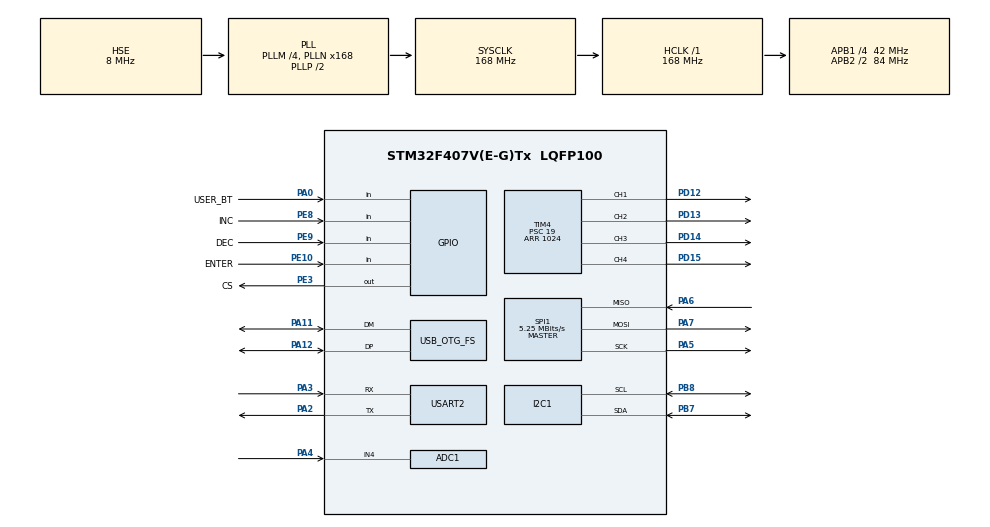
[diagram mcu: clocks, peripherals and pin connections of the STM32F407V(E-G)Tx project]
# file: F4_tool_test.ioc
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ADC1.Channel-5\#ChannelRegularConversion=ADC_CHANNEL_4
ADC1.ClockPrescaler=ADC_CLOCK_SYNC_PCLK_DIV8
ADC1.ContinuousConvMode=ENABLE
ADC1.EOCSelection=ADC_EOC_SEQ_CONV
ADC1.InjNumberOfConversion=0
ADC1.NbrOfConversion=1
ADC1.NbrOfConversionFlag=1
ADC1.Rank-5\#ChannelRegularConversion=1
ADC1.SamplingTime-5\#ChannelRegularConversion=ADC_SAMPLETIME_480CYCLES
ADC1.master=1
Dma.Request0=USART2_TX
Dma.Request1=USART2_RX
Dma.USART2_RX.1.Direction=DMA_PERIPH_TO_MEMORY
Dma.USART2_RX.1.FIFOMode=DMA_FIFOMODE_DISABLE
Dma.USART2_RX.1.Instance=DMA1_Stream5
Dma.USART2_RX.1.MemDataAlignment=DMA_MDATAALIGN_BYTE
Dma.USART2_RX.1.MemInc=DMA_MINC_ENABLE
Dma.USART2_RX.1.Mode=DMA_CIRCULAR
Dma.USART2_RX.1.PeriphDataAlignment=DMA_PDATAALIGN_BYTE
Dma.USART2_RX.1.PeriphInc=DMA_PINC_DISABLE
Dma.USART2_RX.1.Priority=DMA_PRIORITY_LOW
Dma.USART2_TX.0.Direction=DMA_MEMORY_TO_PERIPH
Dma.USART2_TX.0.FIFOMode=DMA_FIFOMODE_DISABLE
Dma.USART2_TX.0.Instance=DMA1_Stream6
Dma.USART2_TX.0.MemDataAlignment=DMA_MDATAALIGN_BYTE
Dma.USART2_TX.0.MemInc=DMA_MINC_ENABLE
Dma.USART2_TX.0.Mode=DMA_NORMAL
Dma.USART2_TX.0.PeriphDataAlignment=DMA_PDATAALIGN_BYTE
Dma.USART2_TX.0.PeriphInc=DMA_PINC_DISABLE
Dma.USART2_TX.0.Priority=DMA_PRIORITY_LOW
Mcu.Family=STM32F4
Mcu.Name=STM32F407V(E-G)Tx
Mcu.Package=LQFP100
NVIC.DMA1_Stream5_IRQn=true\:0\:0\:false\:false\:true\:false\:true
NVIC.DMA1_Stream6_IRQn=true\:0\:0\:false\:false\:true\:false\:true
NVIC.OTG_FS_IRQn=true\:0\:0\:false\:false\:true\:false\:true
NVIC.PriorityGroup=NVIC_PRIORITYGROUP_4
NVIC.USART2_IRQn=true\:0\:0\:false\:false\:true\:true\:true
PA0-WKUP.GPIO_Label=USER_BT
PA0-WKUP.GPIO_PuPd=GPIO_NOPULL
PA0-WKUP.Signal=GPIO_Input
PA11.Mode=Device_Only
PA11.Signal=USB_OTG_FS_DM
PA12.Mode=Device_Only
PA12.Signal=USB_OTG_FS_DP
PA2.Mode=Asynchronous
PA2.Signal=USART2_TX
PA3.Mode=Asynchronous
PA3.Signal=USART2_RX
PA4.Signal=ADCx_IN4
PA5.Mode=Full_Duplex_Master
PA5.Signal=SPI1_SCK
PA6.Mode=Full_Duplex_Master
PA6.Signal=SPI1_MISO
PA7.Mode=Full_Duplex_Master
PA7.Signal=SPI1_MOSI
PB7.Mode=I2C
PB7.Signal=I2C1_SDA
PB8.Mode=I2C
PB8.Signal=I2C1_SCL
PD12.Signal=S_TIM4_CH1
PD13.Signal=S_TIM4_CH2
PD14.Signal=S_TIM4_CH3
PD15.Signal=S_TIM4_CH4
PE10.GPIO_Label=ENTER
PE10.GPIO_PuPd=GPIO_PULLDOWN
PE10.Signal=GPIO_Input
PE3.GPIO_Label=CS
PE3.GPIO_Speed=GPIO_SPEED_FREQ_VERY_HIGH
PE3.PinState=GPIO_PIN_SET
PE3.Signal=GPIO_Output
PE8.GPIO_Label=INC
PE8.GPIO_PuPd=GPIO_PULLDOWN
PE8.Signal=GPIO_Input
PE9.GPIO_Label=DEC
PE9.GPIO_PuPd=GPIO_PULLUP
PE9.Signal=GPIO_Input
PH0-OSC_IN.Mode=HSE-External-Oscillator
PH0-OSC_IN.Signal=RCC_OSC_IN
PH1-OSC_OUT.Mode=HSE-External-Oscillator
PH1-OSC_OUT.Signal=RCC_OSC_OUT
ProjectManager.HeapSize=0x200
ProjectManager.StackSize=0x400
ProjectManager.TargetToolchain=STM32CubeIDE
RCC.48MHZClocksFreq_Value=48000000
RCC.AHBFreq_Value=168000000
RCC.APB1CLKDivider=RCC_HCLK_DIV4
RCC.APB1Freq_Value=42000000
RCC.APB1TimFreq_Value=84000000
RCC.APB2CLKDivider=RCC_HCLK_DIV2
RCC.APB2Freq_Value=84000000
RCC.APB2TimFreq_Value=168000000
RCC.CortexFreq_Value=168000000
RCC.HCLKFreq_Value=168000000
RCC.HSE_VALUE=8000000
RCC.HSI_VALUE=16000000
RCC.LSE_VALUE=32768
RCC.PLLM=4
RCC.PLLN=168
RCC.PLLQ=7
RCC.SYSCLKFreq_VALUE=168000000
RCC.SYSCLKSource=RCC_SYSCLKSOURCE_PLLCLK
RCC.VCOOutputFreq_Value=336000000
SH.ADCx_IN4.0=ADC1_IN4,IN4
SH.S_TIM4_CH1.0=TIM4_CH1,PWM Generation1 CH1
SH.S_TIM4_CH2.0=TIM4_CH2,PWM Generation2 CH2
SH.S_TIM4_CH3.0=TIM4_CH3,PWM Generation3 CH3
SH.S_TIM4_CH4.0=TIM4_CH4,PWM Generation4 CH4
SPI1.BaudRatePrescaler=SPI_BAUDRATEPRESCALER_16
SPI1.CalculateBaudRate=5.25 MBits/s
SPI1.Direction=SPI_DIRECTION_2LINES
SPI1.Mode=SPI_MODE_MASTER
SPI1.VirtualType=VM_MASTER
TIM4.Channel-PWM\ Generation1\ CH1=TIM_CHANNEL_1
TIM4.Channel-PWM\ Generation2\ CH2=TIM_CHANNEL_2
TIM4.Channel-PWM\ Generation3\ CH3=TIM_CHANNEL_3
TIM4.Channel-PWM\ Generation4\ CH4=TIM_CHANNEL_4
TIM4.Period=1024
TIM4.Prescaler=19
USART2.VirtualMode=VM_ASYNC
USB_DEVICE.CLASS_NAME_FS=CDC
USB_DEVICE.VirtualMode-CDC_FS=Cdc
USB_DEVICE.VirtualModeFS=Cdc_FS
USB_OTG_FS.VirtualMode=Device_Only
VP_USB_DEVICE_VS_USB_DEVICE_CDC_FS.Mode=CDC_FS
board=custom

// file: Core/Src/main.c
/* USER CODE BEGIN Header */
/**
  ******************************************************************************
  * @file           : main.c
  * @brief          : Main program body
  ******************************************************************************
  * @attention
  *
  * <h2><center>&copy; Copyright (c) 2021 STMicroelectronics.
  * All rights reserved.</center></h2>
  *
  * This software component is licensed by ST under Ultimate Liberty license
  * SLA0044, the "License"; You may not use this file except in compliance with
  * the License. You may obtain a copy of the License at:
  *                             www.st.com/SLA0044
  *
  ******************************************************************************
  */
/* USER CODE END Header */
#include "main.h"
#include "usb_device.h"

/* USER CODE BEGIN Includes */
#include "usbd_cdc_if.h"
/* USER CODE END Includes */

ADC_HandleTypeDef hadc1;

I2C_HandleTypeDef hi2c1;

SPI_HandleTypeDef hspi1;

TIM_HandleTypeDef htim4;

UART_HandleTypeDef huart2;
DMA_HandleTypeDef hdma_usart2_tx;
DMA_HandleTypeDef hdma_usart2_rx;

void SystemClock_Config(void);
static void MX_GPIO_Init(void);
static void MX_DMA_Init(void);
static void MX_SPI1_Init(void);
static void MX_USART2_UART_Init(void);
static void MX_I2C1_Init(void);
static void MX_ADC1_Init(void);
static void MX_TIM4_Init(void);

int main(void)
{

  /* MCU Configuration--------------------------------------------------------*/

  /* Reset of all peripherals, Initializes the Flash interface and the Systick. */
  HAL_Init();

  /* Configure the system clock */
  SystemClock_Config();

  /* Initialize all configured peripherals */
  MX_GPIO_Init();
  MX_DMA_Init();
  MX_SPI1_Init();
  MX_USART2_UART_Init();
  MX_I2C1_Init();
  MX_USB_DEVICE_Init();
  MX_ADC1_Init();
  MX_TIM4_Init();
  /* USER CODE BEGIN 2 */
setup();
  /* USER CODE END 2 */

  /* Infinite loop */
  /* USER CODE BEGIN WHILE */
  while (1)
  {
	  loop();
    /* USER CODE END WHILE */

  }
}

void SystemClock_Config(void)
{
  RCC_OscInitTypeDef RCC_OscInitStruct = {0};
  RCC_ClkInitTypeDef RCC_ClkInitStruct = {0};

  /** Configure the main internal regulator output voltage
  */
  __HAL_RCC_PWR_CLK_ENABLE();
  __HAL_PWR_VOLTAGESCALING_CONFIG(PWR_REGULATOR_VOLTAGE_SCALE1);
  /** Initializes the RCC Oscillators according to the specified parameters
  * in the RCC_OscInitTypeDef structure.
  */
  RCC_OscInitStruct.OscillatorType = RCC_OSCILLATORTYPE_HSE;
  RCC_OscInitStruct.HSEState = RCC_HSE_ON;
  RCC_OscInitStruct.PLL.PLLState = RCC_PLL_ON;
  RCC_OscInitStruct.PLL.PLLSource = RCC_PLLSOURCE_HSE;
  RCC_OscInitStruct.PLL.PLLM = 4;
  RCC_OscInitStruct.PLL.PLLN = 168;
  RCC_OscInitStruct.PLL.PLLP = RCC_PLLP_DIV2;
  RCC_OscInitStruct.PLL.PLLQ = 7;
  if (HAL_RCC_OscConfig(&RCC_OscInitStruct) != HAL_OK)
  {
    Error_Handler();
  }
  /** Initializes the CPU, AHB and APB buses clocks
  */
  RCC_ClkInitStruct.ClockType = RCC_CLOCKTYPE_HCLK|RCC_CLOCKTYPE_SYSCLK
                              |RCC_CLOCKTYPE_PCLK1|RCC_CLOCKTYPE_PCLK2;
  RCC_ClkInitStruct.SYSCLKSource = RCC_SYSCLKSOURCE_PLLCLK;
  RCC_ClkInitStruct.AHBCLKDivider = RCC_SYSCLK_DIV1;
  RCC_ClkInitStruct.APB1CLKDivider = RCC_HCLK_DIV4;
  RCC_ClkInitStruct.APB2CLKDivider = RCC_HCLK_DIV2;

  if (HAL_RCC_ClockConfig(&RCC_ClkInitStruct, FLASH_LATENCY_5) != HAL_OK)
  {
    Error_Handler();
  }
}

static void MX_ADC1_Init(void)
{

  ADC_ChannelConfTypeDef sConfig = {0};

  /** Configure the global features of the ADC (Clock, Resolution, Data Alignment and number of conversion)
  */
  hadc1.Instance = ADC1;
  hadc1.Init.ClockPrescaler = ADC_CLOCK_SYNC_PCLK_DIV8;
  hadc1.Init.Resolution = ADC_RESOLUTION_12B;
  hadc1.Init.ScanConvMode = DISABLE;
  hadc1.Init.ContinuousConvMode = ENABLE;
  hadc1.Init.DiscontinuousConvMode = DISABLE;
  hadc1.Init.ExternalTrigConvEdge = ADC_EXTERNALTRIGCONVEDGE_NONE;
  hadc1.Init.ExternalTrigConv = ADC_SOFTWARE_START;
  hadc1.Init.DataAlign = ADC_DATAALIGN_RIGHT;
  hadc1.Init.NbrOfConversion = 1;
  hadc1.Init.DMAContinuousRequests = DISABLE;
  hadc1.Init.EOCSelection = ADC_EOC_SEQ_CONV;
  if (HAL_ADC_Init(&hadc1) != HAL_OK)
  {
    Error_Handler();
  }
  /** Configure for the selected ADC regular channel its corresponding rank in the sequencer and its sample time.
  */
  sConfig.Channel = ADC_CHANNEL_4;
  sConfig.Rank = 1;
  sConfig.SamplingTime = ADC_SAMPLETIME_480CYCLES;
  if (HAL_ADC_ConfigChannel(&hadc1, &sConfig) != HAL_OK)
  {
    Error_Handler();
  }

}

static void MX_I2C1_Init(void)
{

  hi2c1.Instance = I2C1;
  hi2c1.Init.ClockSpeed = 100000;
  hi2c1.Init.DutyCycle = I2C_DUTYCYCLE_2;
  hi2c1.Init.OwnAddress1 = 0;
  hi2c1.Init.AddressingMode = I2C_ADDRESSINGMODE_7BIT;
  hi2c1.Init.DualAddressMode = I2C_DUALADDRESS_DISABLE;
  hi2c1.Init.OwnAddress2 = 0;
  hi2c1.Init.GeneralCallMode = I2C_GENERALCALL_DISABLE;
  hi2c1.Init.NoStretchMode = I2C_NOSTRETCH_DISABLE;
  if (HAL_I2C_Init(&hi2c1) != HAL_OK)
  {
    Error_Handler();
  }

}

static void MX_SPI1_Init(void)
{

  /* SPI1 parameter configuration*/
  hspi1.Instance = SPI1;
  hspi1.Init.Mode = SPI_MODE_MASTER;
  hspi1.Init.Direction = SPI_DIRECTION_2LINES;
  hspi1.Init.DataSize = SPI_DATASIZE_8BIT;
  hspi1.Init.CLKPolarity = SPI_POLARITY_LOW;
  hspi1.Init.CLKPhase = SPI_PHASE_1EDGE;
  hspi1.Init.NSS = SPI_NSS_SOFT;
  hspi1.Init.BaudRatePrescaler = SPI_BAUDRATEPRESCALER_16;
  hspi1.Init.FirstBit = SPI_FIRSTBIT_MSB;
  hspi1.Init.TIMode = SPI_TIMODE_DISABLE;
  hspi1.Init.CRCCalculation = SPI_CRCCALCULATION_DISABLE;
  hspi1.Init.CRCPolynomial = 10;
  if (HAL_SPI_Init(&hspi1) != HAL_OK)
  {
    Error_Handler();
  }

}

static void MX_TIM4_Init(void)
{

  TIM_MasterConfigTypeDef sMasterConfig = {0};
  TIM_OC_InitTypeDef sConfigOC = {0};

  htim4.Instance = TIM4;
  htim4.Init.Prescaler = 19;
  htim4.Init.CounterMode = TIM_COUNTERMODE_UP;
  htim4.Init.Period = 1024;
  htim4.Init.ClockDivision = TIM_CLOCKDIVISION_DIV1;
  htim4.Init.AutoReloadPreload = TIM_AUTORELOAD_PRELOAD_DISABLE;
  if (HAL_TIM_PWM_Init(&htim4) != HAL_OK)
  {
    Error_Handler();
  }
  sMasterConfig.MasterOutputTrigger = TIM_TRGO_RESET;
  sMasterConfig.MasterSlaveMode = TIM_MASTERSLAVEMODE_DISABLE;
  if (HAL_TIMEx_MasterConfigSynchronization(&htim4, &sMasterConfig) != HAL_OK)
  {
    Error_Handler();
  }
  sConfigOC.OCMode = TIM_OCMODE_PWM1;
  sConfigOC.Pulse = 0;
  sConfigOC.OCPolarity = TIM_OCPOLARITY_HIGH;
  sConfigOC.OCFastMode = TIM_OCFAST_DISABLE;
  if (HAL_TIM_PWM_ConfigChannel(&htim4, &sConfigOC, TIM_CHANNEL_1) != HAL_OK)
  {
    Error_Handler();
  }
  if (HAL_TIM_PWM_ConfigChannel(&htim4, &sConfigOC, TIM_CHANNEL_2) != HAL_OK)
  {
    Error_Handler();
  }
  if (HAL_TIM_PWM_ConfigChannel(&htim4, &sConfigOC, TIM_CHANNEL_3) != HAL_OK)
  {
    Error_Handler();
  }
  if (HAL_TIM_PWM_ConfigChannel(&htim4, &sConfigOC, TIM_CHANNEL_4) != HAL_OK)
  {
    Error_Handler();
  }
  HAL_TIM_MspPostInit(&htim4);

}

static void MX_USART2_UART_Init(void)
{

  huart2.Instance = USART2;
  huart2.Init.BaudRate = 115200;
  huart2.Init.WordLength = UART_WORDLENGTH_8B;
  huart2.Init.StopBits = UART_STOPBITS_1;
  huart2.Init.Parity = UART_PARITY_NONE;
  huart2.Init.Mode = UART_MODE_TX_RX;
  huart2.Init.HwFlowCtl = UART_HWCONTROL_NONE;
  huart2.Init.OverSampling = UART_OVERSAMPLING_16;
  if (HAL_UART_Init(&huart2) != HAL_OK)
  {
    Error_Handler();
  }

}

static void MX_DMA_Init(void)
{

  /* DMA controller clock enable */
  __HAL_RCC_DMA1_CLK_ENABLE();

  /* DMA interrupt init */
  /* DMA1_Stream5_IRQn interrupt configuration */
  HAL_NVIC_SetPriority(DMA1_Stream5_IRQn, 0, 0);
  HAL_NVIC_EnableIRQ(DMA1_Stream5_IRQn);
  /* DMA1_Stream6_IRQn interrupt configuration */
  HAL_NVIC_SetPriority(DMA1_Stream6_IRQn, 0, 0);
  HAL_NVIC_EnableIRQ(DMA1_Stream6_IRQn);

}

static void MX_GPIO_Init(void)
{
  GPIO_InitTypeDef GPIO_InitStruct = {0};

  /* GPIO Ports Clock Enable */
  __HAL_RCC_GPIOE_CLK_ENABLE();
  __HAL_RCC_GPIOH_CLK_ENABLE();
  __HAL_RCC_GPIOA_CLK_ENABLE();
  __HAL_RCC_GPIOD_CLK_ENABLE();
  __HAL_RCC_GPIOB_CLK_ENABLE();

  /*Configure GPIO pin Output Level */
  HAL_GPIO_WritePin(CS_GPIO_Port, CS_Pin, GPIO_PIN_SET);

  /*Configure GPIO pin : CS_Pin */
  GPIO_InitStruct.Pin = CS_Pin;
  GPIO_InitStruct.Mode = GPIO_MODE_OUTPUT_PP;
  GPIO_InitStruct.Pull = GPIO_NOPULL;
  GPIO_InitStruct.Speed = GPIO_SPEED_FREQ_VERY_HIGH;
  HAL_GPIO_Init(CS_GPIO_Port, &GPIO_InitStruct);

  /*Configure GPIO pin : USER_BT_Pin */
  GPIO_InitStruct.Pin = USER_BT_Pin;
  GPIO_InitStruct.Mode = GPIO_MODE_INPUT;
  GPIO_InitStruct.Pull = GPIO_NOPULL;
  HAL_GPIO_Init(USER_BT_GPIO_Port, &GPIO_InitStruct);

  /*Configure GPIO pins : INC_Pin ENTER_Pin */
  GPIO_InitStruct.Pin = INC_Pin|ENTER_Pin;
  GPIO_InitStruct.Mode = GPIO_MODE_INPUT;
  GPIO_InitStruct.Pull = GPIO_PULLDOWN;
  HAL_GPIO_Init(GPIOE, &GPIO_InitStruct);

  /*Configure GPIO pin : DEC_Pin */
  GPIO_InitStruct.Pin = DEC_Pin;
  GPIO_InitStruct.Mode = GPIO_MODE_INPUT;
  GPIO_InitStruct.Pull = GPIO_PULLUP;
  HAL_GPIO_Init(DEC_GPIO_Port, &GPIO_InitStruct);

}

void Error_Handler(void)
{
  __disable_irq();
  while (1)
  {
  }
}

/************************ (C) COPYRIGHT STMicroelectronics *****END OF FILE****/
